# STM32WL3R register map
File version: 1.0
CPU: CM0+ r0p0, little endian, MPU, no FPU, 4 interrupt priority bits
Registers are 32-bit, read-write, reset 0x0 unless marked. A register's access mark holds for its fields unless they carry their own. Offsets are from the block's base; [hi:lo] are bit positions; {n}, {i} and the like mark numbered series; 'fields as' and 'values as' point back to an identical list.

## ADC — ADC address block description
Base 0x41006000
0x00 VERSION_ID ro reset 0x21
  [7:0] VERSION_ID — VERSION_ID[7:0]: version of the embedded IP.
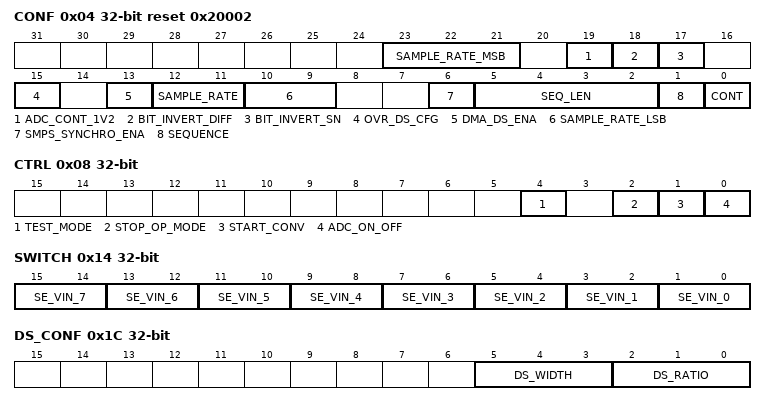
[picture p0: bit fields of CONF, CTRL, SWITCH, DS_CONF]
0x04 CONF reset 0x20002 (reset mask 0xFFFFF)
  [23:21] SAMPLE_RATE_MSB — SAMPLE_RATE_MSB: Sample Rate MSB
  [19] ADC_CONT_1V2 — ADC_CONT_1V2: select the input sampling method:
  [18] BIT_INVERT_DIFF — BIT_INVERT_DIFF: invert bit to bit the ADC data output (1's complement) when a differential
  [17] BIT_INVERT_SN — BIT_INVERT_SN: invert bit to bit the ADC data output (1's complement) when a single
  [15] OVR_DS_CFG — OVR_DS_CFG: Down Sampler overrun configuration:
  [13] DMA_DS_ENA — DMA_DS_EN: enable the DMA mode for the Down Sampler data path:
  [12:11] SAMPLE_RATE — SAMPLE_RATE[1:0]: conversion rate of ADC (F_ADC):
  [10:9] SAMPLE_RATE_LSB — SAMPLE_RATE_LSB: Sample Rate LSB
  [6] SMPS_SYNCHRO_ENA — SMPS_SYNCHRO_ENA: synchronize the ADC start conversion with a pulse generated by the
  [5:2] SEQ_LEN — SEQ_LEN[3:0]: number of conversions in a regular sequence:
  [1] SEQUENCE — SEQUENCE: enable the sequence mode (active by default):
  [0] CONT — CONT: regular sequence runs continuously when ADC mode is enabled:
0x08 CTRL (reset mask 0xF)
  [4] TEST_MODE — TEST_MODE: select the functional or the test mode of the ADC:
  [2] STOP_OP_MODE wo — STOP_OP_MODE (1): stop the on-going OP_MODE (ADC mode, Analog audio mode, Full
  [1] START_CONV wo — START_CONV (1): generate a start pulse to initiate an ADC conversion:
  [0] ADC_ON_OFF
0x14 SWITCH (reset mask 0xF)
  [2n+1:2n] SE_VIN_{n} (n=4..7) — SE_VIN_{n}[1:0]: input voltage for VINP[{n-4}]
  [2n+1:2n] SE_VIN_{n} (n=0..3) — SE_VIN_{n}[1:0]: input voltage for VINM[{n}] / VINP[{n}]-VINM[{n}]
0x1C DS_CONF (reset mask 0xF)
  [5:3] DS_WIDTH — DS_WIDTH[2:0]: program the Down Sampler width of data output (DSDTATA)
  [2:0] DS_RATIO — DS_RATIO[2:0]: program the Down Sampler ratio (N factor)
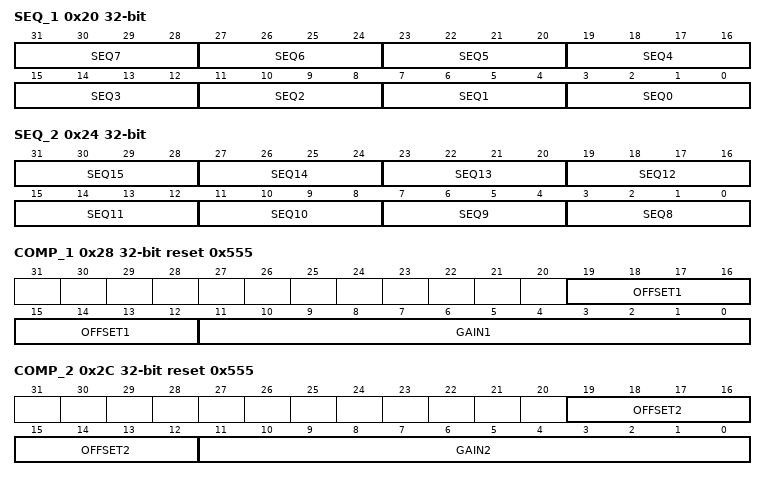
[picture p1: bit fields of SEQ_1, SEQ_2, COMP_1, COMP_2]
0x20 SEQ_1 (reset mask 0xF)
  [4n+3:4n] SEQ{n} (n=3..7) — SEQ{n}[3:0]: channel number code for {n+1}th conversion of the sequence.
  [11:8] SEQ2 — SEQ2[3:0]: channel number code for 3rd conversion of the sequence.
  [7:4] SEQ1 — SEQ1[3:0]: channel number code for second conversion of the sequence.
  [3:0] SEQ0 — SEQ0[3:0]: channel number code for first conversion of the sequence
0x24 SEQ_2 (reset mask 0xF)
  [4n-29:4n-32] SEQ{n} (n=9..15) — SEQ{n}[3:0]: channel number code for {n+1}th conversion of the sequence.
  [3:0] SEQ8 — SEQ8[3:0]: channel number code for 9th conversion of the sequence
0x28 COMP_1 reset 0x555
  [19:12] OFFSET1 — OFFSET1[7:0]: first calibration point
  [11:0] GAIN1 — GAIN1[11:0]: first calibration point: gain AUXADC_GAIN_1V2[11:0]
0x2C COMP_2 reset 0x555
  [19:12] OFFSET2 — OFFSET2[7:0]: second calibration point
  [11:0] GAIN2 — GAIN2[11:0]: second calibration point: gain AUXADC_GAIN_1V2[11:0]
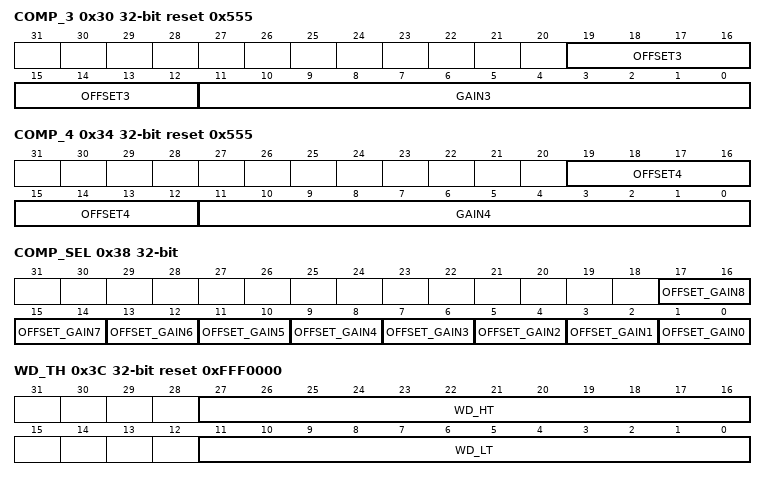
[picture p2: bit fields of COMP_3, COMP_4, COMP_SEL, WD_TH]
0x30 COMP_3 reset 0x555
  [19:12] OFFSET3 — OFFSET3[7:0]: third calibration point
  [11:0] GAIN3 — GAIN3[11:0]: third calibration point: gain AUXADC_GAIN_1V2[11:0]
0x34 COMP_4 reset 0x555
  [19:12] OFFSET4 — OFFSET4[7:0]: fourth calibration point
  [11:0] GAIN4 — GAIN4[11:0]: fourth calibration point: gain AUXADC_GAIN_1V2[11:0]
0x38 COMP_SEL (reset mask 0xF)
  [17:16] OFFSET_GAIN8 — OFFSET_GAIN8[1:0]: gain / offset used in ADC differential mode with Vinput range = 3.
  [15:14] OFFSET_GAIN7 — OFFSET_GAIN7[1:0]: gain / offset used in ADC single positive mode with Vinput range =
  [13:12] OFFSET_GAIN6 — OFFSET_GAIN6[1:0]: gain / offset used in ADC single negative mode with Vinput range =
  [11:10] OFFSET_GAIN5 — OFFSET_GAIN5[1:0]: gain / offset used in ADC differential mode with Vinput range = 2.
  [9:8] OFFSET_GAIN4 — OFFSET_GAIN4[1:0]: gain / offset used in ADC single positive mode with Vinput range =
  [7:6] OFFSET_GAIN3 — OFFSET_GAIN3[1:0]: gain / offset used in ADC single negative mode with Vinput range =
  [5:4] OFFSET_GAIN2 — OFFSET_GAIN2[1:0]: gain / offset used in ADC differential mode with Vinput range = 1.
  [3:2] OFFSET_GAIN1 — OFFSET_GAIN1[1:0]: gain / offset used in ADC single positive mode with Vinput range =
  [1:0] OFFSET_GAIN0 — OFFSET_GAIN0[1:0]: gain / offset used in ADC single negative mode with Vinput range =
0x3C WD_TH reset 0xFFF0000
  [27:16] WD_HT — WD_HT[11:0]: analog watchdog high level threshold.
  [11:0] WD_LT — WD_LT[11:0]: analog watchdog low level threshold.
0x40 WD_CONF (reset mask 0xF)
  [15:0] AWD_CHX — AWD_CHX[15:0]: analog watchdog channel selection to define which input channel(s) need
0x44 DS_DATAOUT ro (reset mask 0xF)
  [15:0] DS_DATA — DS_DATA[15:0]: contain the converted data at the output of the Down Sampler.
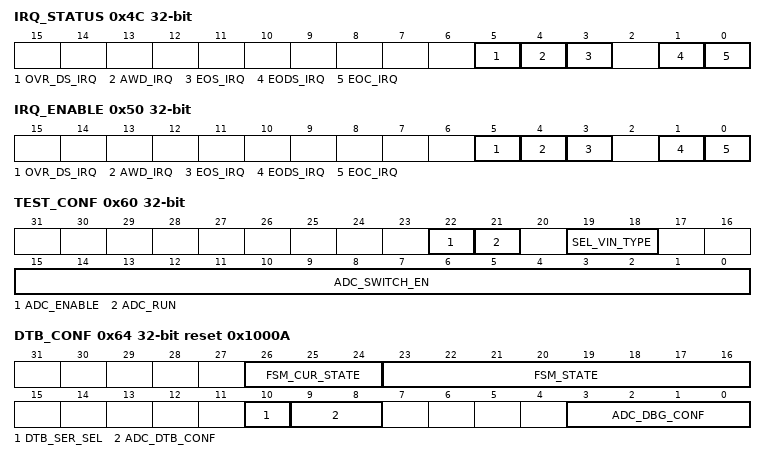
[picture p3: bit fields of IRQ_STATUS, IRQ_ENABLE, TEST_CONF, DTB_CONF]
0x4C IRQ_STATUS (reset mask 0xF)
  [5] OVR_DS_IRQ — OVR_DS_IRQ: set to indicate a Down Sampler overrun (at least one data is lost)
  [4] AWD_IRQ — AWD_IRQ: set when an analog watchdog event occurs.
  [3] EOS_IRQ — EOS_IRQ: set when a sequence of conversion is completed.
  [1] EODS_IRQ — EODS_IRQ: set when the Down Sampler conversion is completed.
  [0] EOC_IRQ — EOC_IRQ (Used in test mode only): set when the ADC conversion is completed.
0x50 IRQ_ENABLE (reset mask 0xF)
  fields as IRQ_STATUS
0x60 TEST_CONF (reset mask 0xF)
  [22] ADC_ENABLE
  [21] ADC_RUN — ADC_RUN: Start/stop ADC conversion.
  [19:18] SEL_VIN_TYPE — SEL_VIN_TYPE[1:0]: operation mode of the selected VIN
  [15:0] ADC_SWITCH_EN — ADC_SWITCH_EN[15:0]: enable individually each connection of the switching matrix at the
0x64 DTB_CONF reset 0x1000A (reset mask 0xFFFFF)
  [26:24] FSM_CUR_STATE ro — FSM_CUR_STATE[2:0]: show the last executed state by the state machine.
  [23:16] FSM_STATE ro — FSM_STATE[7:0]: show the state of the state machine.
  [10] DTB_SER_SEL — DTB_SER_SEL: DTB serial output selection when ADC_DB_CONF[1:0]=3d
  [9:8] ADC_DTB_CONF — ADC_DTB_CONF[1:0]: configure the DTB output.
  [3:0] ADC_DBG_CONF — ADC_DBG_CONF[3:0]: use for debug purpose.
